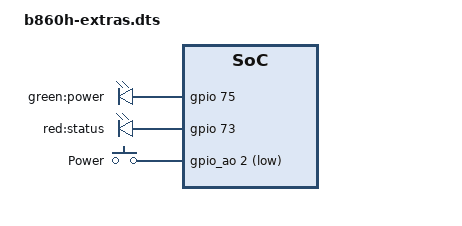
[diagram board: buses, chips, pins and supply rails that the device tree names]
/dts-v1/;
/plugin/;

/* ZTE B860H extras applied on top of the kernel's stock meson-gxl-s905x-p212.dtb */
/ {
	/*
	 * Wi-Fi: the P212 reference board releases the SDIO Wi-Fi chip from reset with GPIO 85, the B860H
	 * uses GPIO 76 (value taken from ophub's meson-gxl-s905x-b860h.dtb, where the chip is then detected).
	 * With the stock pin the chip never shows up on the SDIO bus.
	 */
	fragment@1 {
		target = <&sdio_pwrseq>;
		__overlay__ {
			reset-gpios = <&gpio 76 1>;
		};
	};

	/*
	 * Bluetooth: the P212 reference tree has a Broadcom BCM43438 Bluetooth chip on UART A. No B860H variant
	 * has one (RTL8189FTV is Wi-Fi only, MT7668RSN would be a MediaTek part), so the kernel just times out
	 * on it at every boot ("BCM: Reset failed (-110)"). Switch the node off.
	 */
	fragment@2 {
		target-path = "/soc/bus@c1100000/serial@84c0/bluetooth";
		__overlay__ {
			status = "disabled";
		};
	};

	fragment@0 {
		target-path = "/";
		__overlay__ {
			leds {
				compatible = "gpio-leds";

				led-green {
					label = "green:power";
					gpios = <&gpio 75 0>;
					linux,default-trigger = "default-on";
				};

				led-red {
					label = "red:status";
					gpios = <&gpio 73 0>;
					linux,default-trigger = "activity";
					panic-indicator;
				};
			};

			/* The GXL GPIO irq controller can't do both-edge irqs, so poll the button */
			gpio-keys-polled {
				compatible = "gpio-keys-polled";
				poll-interval = <100>;

				power-button {
					label = "Power";
					linux,code = <116>;
					gpios = <&gpio_ao 2 1>;
				};
			};
		};
	};
};
